VERSION ""

NS_ :

BS_:

BU_:

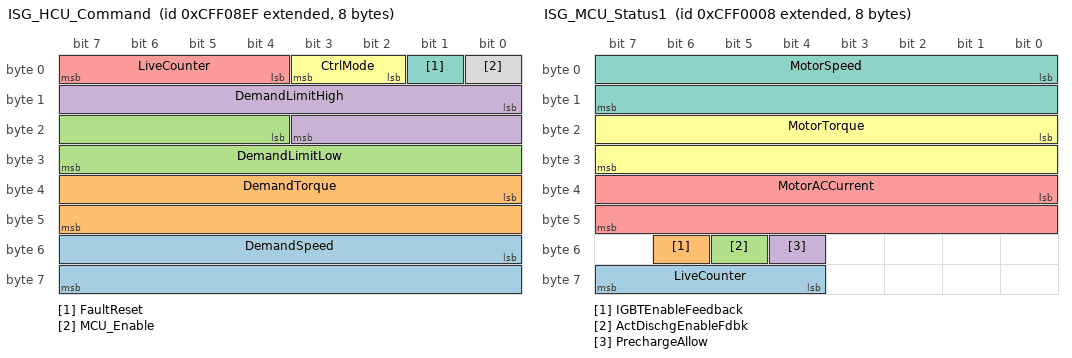
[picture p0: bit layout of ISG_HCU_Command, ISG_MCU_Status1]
BO_ 2365524207 ISG_HCU_Command: 8 HCU
 SG_ DemandSpeed : 48|16@1+ (1.0,-15000.0) [-15000.0|15000.0] "rpm"  MCU
 SG_ DemandTorque : 32|16@1+ (1.0,-5000.0) [-5000.0|5000.0] "Nm"  MCU
 SG_ DemandLimitLow : 20|12@1+ (1,0) [0.0|4095.0] ""  MCU
 SG_ DemandLimitHigh : 8|12@1+ (1,0) [0.0|4095.0] ""  MCU
 SG_ LiveCounter : 4|4@1+ (1,0) [0.0|15.0] ""  MCU
 SG_ CtrlMode : 2|2@1+ (1,0) [0.0|3.0] ""  MCU
 SG_ FaultReset : 1|1@1+ (1,0) [0.0|1.0] ""  MCU
 SG_ MCU_Enable : 0|1@1+ (1,0) [0.0|1.0] ""  MCU

BO_ 2365521928 ISG_MCU_Status1: 8 MCU
 SG_ LiveCounter : 60|4@1+ (1,0) [0.0|15.0] ""  HCU
 SG_ IGBTEnableFeedback : 54|1@1+ (1,0) [0.0|1.0] ""  HCU
 SG_ ActDischgEnableFdbk : 53|1@1+ (1,0) [0.0|1.0] ""  HCU
 SG_ PrechargeAllow : 52|1@1+ (1,0) [0.0|1.0] ""  HCU
 SG_ MotorACCurrent : 32|16@1+ (0.1,0.0) [0.0|1000.0] "A"  HCU
 SG_ MotorTorque : 16|16@1+ (1.0,-5000.0) [-5000.0|5000.0] "Nm"  HCU
 SG_ MotorSpeed : 0|16@1+ (1.0,-15000.0) [-15000.0|15000.0] "rpm"  HCU

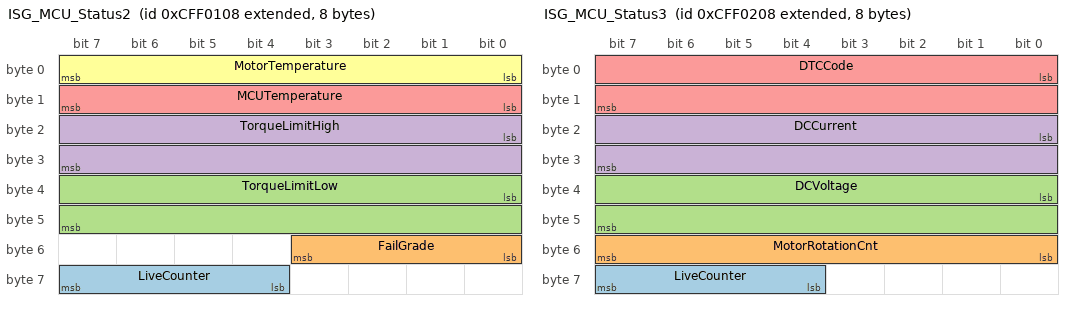
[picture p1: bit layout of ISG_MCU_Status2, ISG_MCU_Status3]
BO_ 2365522184 ISG_MCU_Status2: 8 MCU
 SG_ LiveCounter : 60|4@1+ (1,0) [0.0|15.0] ""  HCU
 SG_ FailGrade : 48|4@1+ (1,0) [0.0|4.0] ""  HCU
 SG_ TorqueLimitLow : 32|16@1+ (1.0,-5000.0) [-5000.0|0.0] "Nm"  HCU
 SG_ TorqueLimitHigh : 16|16@1+ (1,0) [0.0|5000.0] "Nm"  HCU
 SG_ MCUTemperature : 8|8@1+ (1.0,-40.0) [-40.0|215.0] "℃"  HCU
 SG_ MotorTemperature : 0|8@1+ (1.0,-40.0) [-40.0|215.0] "℃"  HCU

BO_ 2365522440 ISG_MCU_Status3: 8 MCU
 SG_ LiveCounter : 60|4@1+ (1,0) [0.0|15.0] ""  HCU
 SG_ MotorRotationCnt : 48|8@1+ (1,0) [0.0|255.0] "转"  HCU
 SG_ DCVoltage : 32|16@1+ (0.1,0.0) [0.0|1000.0] "V"  HCU
 SG_ DCCurrent : 16|16@1+ (1.0,-1000.0) [-1000.0|1000.0] "A"  HCU
 SG_ DTCCode : 0|16@1+ (1,0) [0.0|65535.0] ""  HCU

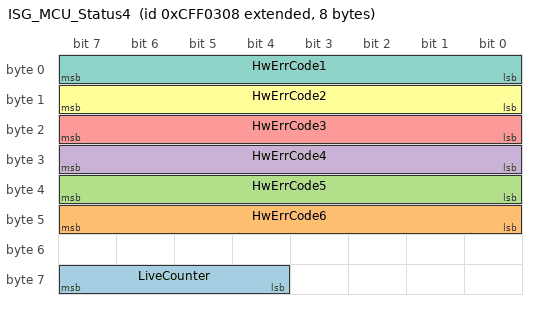
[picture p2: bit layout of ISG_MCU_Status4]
BO_ 2365522696 ISG_MCU_Status4: 8 MCU
 SG_ LiveCounter : 60|4@1+ (1,0) [0.0|15.0] ""  HCU
 SG_ HwErrCode6 : 40|8@1+ (1,0) [0.0|255.0] ""  HCU
 SG_ HwErrCode5 : 32|8@1+ (1,0) [0.0|255.0] ""  HCU
 SG_ HwErrCode4 : 24|8@1+ (1,0) [0.0|255.0] ""  HCU
 SG_ HwErrCode3 : 16|8@1+ (1,0) [0.0|255.0] ""  HCU
 SG_ HwErrCode2 : 8|8@1+ (1,0) [0.0|255.0] ""  HCU
 SG_ HwErrCode1 : 0|8@1+ (1,0) [0.0|255.0] ""  HCU

CM_ BO_ 2365524207 "period 10ms";
CM_ SG_ 2365524207 DemandSpeed "转速的正负表示电机旋转的方向与发动机正常转动方向同向为正";
CM_ SG_ 2365524207 DemandTorque "转矩的正负表示力的方向规定发动机旋转方向为正向";
CM_ SG_ 2365524207 DemandLimitLow "转矩转速指令限值下限网络上发送的是正数值但电机控制器实际执行按负值处理";
CM_ SG_ 2365524207 DemandLimitHigh "转矩转速指令限值上限转矩控制模式时转速限制起作用转速控制模式时转矩限制起作用转矩单位Nm转速单位rpm缩放系数转矩1转速4";
CM_ SG_ 2365524207 LiveCounter "循环计数器Alive Rolling Counter";
CM_ SG_ 2365524207 CtrlMode "0:Reserved
1:Speed Control
2 = Torque Control
3 = Active Discharge";
CM_ SG_ 2365524207 FaultReset "0:disable
1:enable";
CM_ SG_ 2365524207 MCU_Enable "0:disable
1:enable";
CM_ BO_ 2365521928 "period 10ms";
CM_ SG_ 2365521928 LiveCounter "循环计数器Alive Rolling Counter";
CM_ SG_ 2365521928 IGBTEnableFeedback "0:disable
1:enable";
CM_ SG_ 2365521928 ActDischgEnableFdbk "0:disable
1:enable";
CM_ SG_ 2365521928 PrechargeAllow "0:disable
1:enable";
CM_ SG_ 2365521928 MotorACCurrent "交流侧电流有效值反馈AC Current RMS value feedback";
CM_ SG_ 2365521928 MotorTorque "扭矩大于0为转矩方向与发动机转向相同";
CM_ SG_ 2365521928 MotorSpeed "电机转速正负表示电机转向转速为正时与发动机正常转动方向一致";
CM_ BO_ 2365522184 "period 50ms";
CM_ SG_ 2365522184 LiveCounter "循环计数器Alive Rolling Counter";
CM_ SG_ 2365522184 FailGrade "0:No Fault
1:Warning(degraded)
2 = Fault(zero torque output)
3 = Fault(shut down MCU)
4 = Serious Fault(need to stop the vehicle)";
CM_ SG_ 2365522184 TorqueLimitLow "转矩下限";
CM_ SG_ 2365522184 TorqueLimitHigh "转矩上限";
CM_ SG_ 2365522184 MCUTemperature "电机控制器温度";
CM_ SG_ 2365522184 MotorTemperature "电机本体温度最低温只能测到22度";
CM_ BO_ 2365522440 "period 100ms";
CM_ SG_ 2365522440 LiveCounter "循环计数器Alive Rolling Counter";
CM_ SG_ 2365522440 MotorRotationCnt "电机转数循环计数到255后回0用于记录转了多少圈满255之后清零可以和仪表配合进行精确里程计算";
CM_ SG_ 2365522440 DCVoltage "直流电压";
CM_ SG_ 2365522440 DCCurrent "直流电流估计值不建议作为控制量电机驱动状态为负发电状态为正";
CM_ SG_ 2365522440 DTCCode "错误故障码Diagnostic Trouble Code";
CM_ BO_ 2365522696 "period 100ms";
CM_ SG_ 2365522696 LiveCounter "循环计数器Alive Rolling Counter";
CM_ SG_ 2365522696 HwErrCode6 "1:控制器内部控制电源异常故障5V异常
2 = 外供控制器控制电源异常故障24V输入断线或低于18V";
CM_ SG_ 2365522696 HwErrCode5 "1:编码器断线故障";
CM_ SG_ 2365522696 HwErrCode4 "1:IGBT模块故障";
CM_ SG_ 2365522696 HwErrCode3 "1:电机控制器温度断线故障
2 = 电机控制器过温故障
3 = 电机温度断线故障
4 = 电机温度过温故障";
CM_ SG_ 2365522696 HwErrCode2 "1:硬件限流故障
2 = 硬件过流故障";
CM_ SG_ 2365522696 HwErrCode1 "1:母线电压欠压故障
2 = 母线电压过压故障";
